# cslr_sys register map
Vendor: Texas Instruments
Peripheral module from a debugger description file (folder C5517).
Address unit: 16 bits
Registers are 16-bit, access not given, reset 0x0 unless marked. A register's access mark holds for its fields unless they carry their own. Offsets are as the file gives them; lines under a group give offsets from that group; [hi:lo] are bit positions; {n}, {i} and the like mark numbered series; 'fields as' and 'values as' point back to an identical list; <NAME> marks a mode.

## SYS — The DSP system module controls several features of the DSP, e.g. clock control, DMA event synchronization, PLL settings, and the CLKOUT source.
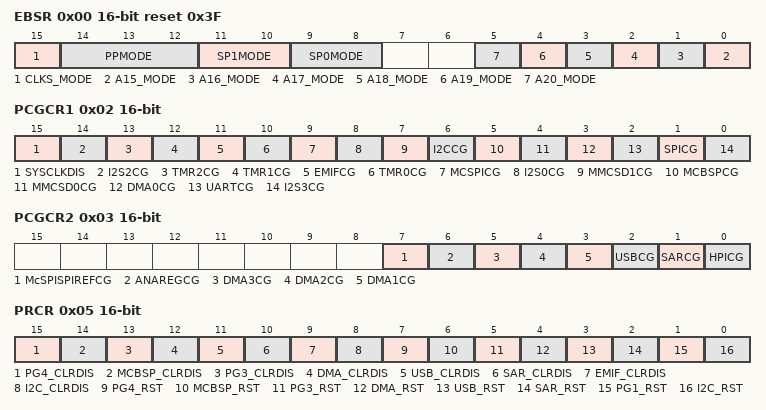
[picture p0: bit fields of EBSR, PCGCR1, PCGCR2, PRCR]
0x00 EBSR reset 0x3F — External Bus Selection Register
  [15] CLKS_MODE ro — McBSP CLKS selection bit.Determines which pin of the McBSP is fed to S05 when the Serial Port 0 Mode is set to 11.
    0=ZERO (McBSP CLKR signal is routed to Serial Port 0 pin S05.); 1=ONE (McBSP CLKS signal is routed to Serial Port 0 pin S05)
  [14:12] PPMODE rw — Parallel port mode bits. These bits control the pin muxing on the parallel port.
    {v}=MODE{v} (v=0..6); 7=MODE7 (Reserved, do not use.)
  [11:10] SP1MODE rw — Serial port 1 mode bits. These bits control the pin muxing on serial port 1.
    0=MODE0; 1=MODE1; 2=MODE2; 3=MODE3 (Mode 3 - Reserved , Do not use.)
  [9:8] SP0MODE rw — Serial port 0 mode bits. These bits control the pin muxing on serial port 0.
    {v}=MODE{v} (v=0..3)
  [n-15] A{n}_MODE rw (n=15..20) — This bit controls the pin multiplexing on EM_A[{n}].
    0=MODE0 (Pin behaves as EM_A[{n}].); 1=MODE1 (Pin behaves as GP[{n+6}].)
0x02 PCGCR1 rw — Peripheral Clock Gating Configuration Register 1
  [15] SYSCLKDIS — System clock disable bit. This bit can be used to turn off the system clock. Setting the WAKEUP pin high enables the system clock. Since the WAKEUP pin is used to re-enable the system clock, the WAKEUP pin must be low to disable the system clock.
    0=ACTIVE (System clock is active.); 1=DISABLED (System clock is disabled.)
  [14] I2S2CG — I2S2 clock gate control bit. This bit is used to enable and disable the I2S2 peripheral clock.
    0=ACTIVE (Peripheral clock is active.); 1=DISABLED (Peripheral clock is disabled.)
  [13] TMR2CG — Timer 2 clock gate control bit. This bit is used to enable and disable the Timer 2 peripheral clock.
    values as I2S2CG
  [12] TMR1CG — Timer 1 clock gate control bit. This bit is used to enable and disable the Timer 1 peripheral clock.
    values as I2S2CG
  [11] EMIFCG — EMIF clock gate control bit. This bit is used to enable and disable the EMIF peripheral clock. NOTE: You must request permission before stopping the EMIF clock through the peripheral clock stop request/acknowledge register (CLKSTOP).
    values as I2S2CG
  [10] TMR0CG — Timer 0 clock gate control bit. This bit is used to enable and disable the Timer 0 peripheral clock.
    values as I2S2CG
  [9] MCSPICG — MCSPI clock gate control bit. This bit is used to enable and disable the MCSPI peripheral clock.
    values as I2S2CG
  [8] I2S0CG — I2S0 clock gate control bit. This bit is used to enable and disable the I2S0 peripheral clock.
    values as I2S2CG
  [7] MMCSD1CG — MMC/SD1 clock gate control bit. This bit is used to enable and disable the MMC/SD1 peripheral clock.
    values as I2S2CG
  [6] I2CCG — I2C clock gate control bit. This bit is used to enable and disable the I2C peripheral clock.
    values as I2S2CG
  [5] MCBSPCG — McBSP clock gate control bit. This bit is used to enable the disable the McBSP peripheral clock
    values as I2S2CG
  [4] MMCSD0CG — MMC/SD0 clock gate control bit. This bit is used to enable and disable the MMC/SD0 peripheral clock.
    values as I2S2CG
  [3] DMA0CG — DMA controller 0 clock gate control bit. This bit is used to enable and disable the peripheral clock the DMA controller 0.
    values as I2S2CG
  [2] UARTCG — UART clock gate control bit. This bit is used to enable and disable the UART peripheral clock. NOTE: You must request permission before stopping the UART clock through the peripheral clock stop request/acknowledge register (CLKSTOP).
    values as I2S2CG
  [1] SPICG — SPI clock gate control bit. This bit is used to enable and disable the SPI controller peripheral clock.
    values as I2S2CG
  [0] I2S3CG — I2S3 clock gate control bit. This bit is used to enable and disable the I2S3 peripheral clock.
    values as I2S2CG
0x03 PCGCR2 — Peripheral Clock Gating Configuration Register 2
  [7] McSPISPIREFCG rw — McSPI SPIREF Clock Gate Control bit. This bit is used to enable and disable the clock to the McSPI SPIREF block.
    values as PCGCR1.I2S2CG
  [6] ANAREGCG rw — Analog registers clock gate control bit. This bit is used to enable and disable the clock to the registers that control the analog domain of the device, i.e. registers in the 7000h-70FFh I/O space address range. NOTE: When SARCG = 0, the clocks to the analog domain registers is enabled regardless of the ANAREGCG setting.
    0=ACTIVE (Clock is active.); 1=DISABLED (Clock is disabled.)
  [5] DMA3CG rw — DMA controller 3 clock gate control bit. This bit is used to enable and disable the peripheral clock the DMA controller 3.
    values as PCGCR1.I2S2CG
  [4] DMA2CG rw — DMA controller 2 clock gate control bit. This bit is used to enable and disable the peripheral clock the DMA controller 2.
    values as PCGCR1.I2S2CG
  [3] DMA1CG rw — DMA controller 1 clock gate control bit. This bit is used to enable and disable the peripheral clock the DMA controller 1.
    values as PCGCR1.I2S2CG
  [2] USBCG rw — USB clock gate control bit. This bit is used to enable and disable the peripheral clock the USB. NOTE: You must request permission before stopping the USB clock through the peripheral clock stop request/acknowledge register (CLKSTOP).
    values as PCGCR1.I2S2CG
  [1] SARCG rw — SAR clock gate control bit. This bit is used to enable and disable the SAR peripheral clock. NOTE: When SARCG = 0, the clocks to the analog domain registers is enabled regardless of the ANAREGCG setting.
    values as PCGCR1.I2S2CG
  [0] HPICG rw — HPI clock gate control bit. This bit is used to enable and disable the HPI peripheral clock.
    values as PCGCR1.I2S2CG
0x04 PSRCR rw — Peripheral Software Reset Counter Register
  [15:0] COUNT — Count bits. These bits specify the number of system clock (SYSCLK) cycles the software reset bits are asserted. When the software counter reaches 0, the software reset bits will be cleared to 0. Always initialize this field with 20h.
0x05 PRCR rw — Peripheral Reset Control Register
  [15] PG4_CLRDIS — Peripheral group 4 self-cleraing software reset disable bit. Drives the HPI, I2S2, I2S3, UART, and SPI reset signal.
    0=ENABLE (self-clearing software reset is enabled.); 1=DISABLE (self-clearing software reset is disabled.)
  [14] MCBSP_CLRDIS — MCBSP self-cleraing software reset disable bit. Drives the MCBSP self-cleraing software reset disable signal.
    values as PG4_CLRDIS
  [13] PG3_CLRDIS — Peripheral group 3 self-cleraing software reset disable bit. Drives the MMC/SD0, MMC/SD1, I2S0, and MCSPI self-cleraing software reset disable signal.
    values as PG4_CLRDIS
  [12] DMA_CLRDIS — DMA self-cleraing software reset disable bit. Drives the self-cleraing software reset disable signal to the DMA controllers.
    values as PG4_CLRDIS
  [11] USB_CLRDIS — USB self-cleraing software reset disable bit. Drives the USB self-cleraing software reset disable signal.
    values as PG4_CLRDIS
  [10] SAR_CLRDIS — Analog registers and SAR self-cleraing software reset disable bit. Drives the analog register and SAR self-cleraing software reset disable signal.
    values as PG4_CLRDIS
  [9] EMIF_CLRDIS — Drives the EMIF self-cleraing software reset disable signal.
    values as PG4_CLRDIS
  [8] I2C_CLRDIS — I2C self-cleraing software reset disable bit. Drives the I2C self-cleraing software reset disable signal.
    values as PG4_CLRDIS
  [7] PG4_RST — Peripheral group 4 software reset bit. Drives the HPI, I2S2, I2S3, UART, and SPI reset signal.
    1=RST (Reset deasserted, modules out of reset.); 0=NRST (Reset asserted, modules in reset.)
  [6] MCBSP_RST — MCBSP software reset bit. Drives the MCBSP reset signal.
    values as PG4_RST
  [5] PG3_RST — Peripheral group 3 software reset bit. Drives the MMC/SD0, MMC/SD1, I2S0, and MCSPI reset signal.
    values as PG4_RST
  [4] DMA_RST — DMA software reset bit. Drives the reset signal to the DMA controllers.
    values as PG4_RST
  [3] USB_RST — USB software reset bit. Drives the USB reset signal.
    1=RST (Reset deasserted, module out of reset.); 0=NRST (Reset asserted, module in reset.)
  [2] SAR_RST — Analog registers and SAR reset bit. Drives the analog register and SAR reset signal.
    values as USB_RST
  [1] PG1_RST — Drives the EMIF and Timer reset signal.
    values as PG4_RST
  [0] I2C_RST — I2C software reset bit. Drives the I2C reset signal.
    values as USB_RST
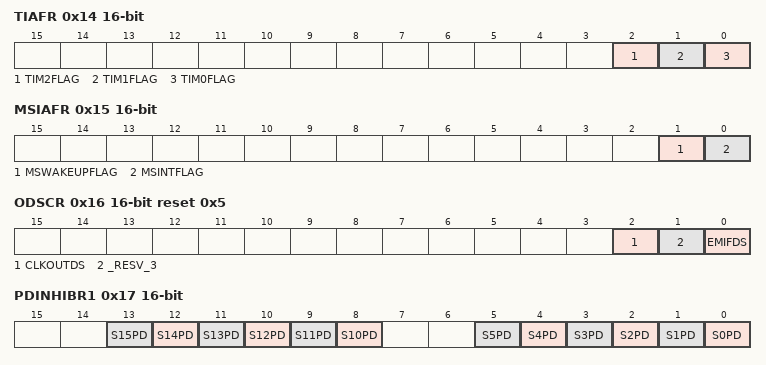
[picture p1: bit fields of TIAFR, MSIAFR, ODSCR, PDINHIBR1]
0x14 TIAFR — Timer Interrupt Aggregation Flag Register
  [all] fields
    0=NOINT (Timer has not generated an interrupt.); 1=INT (Timer interrupt has occurred.)
  [2] TIM2FLAG — Timer 2 interrupt flag bit. This bit latches the timer interrupt signal when the timer counter expires. You can clear this flag bit by writing a 1 to it. (access RW1C)
  [1] TIM1FLAG — Timer 1 interrupt flag bit. This bit latches the timer interrupt signal when the timer counter expires. You can clear this flag bit by writing a 1 to it. (access RW1C)
  [0] TIM0FLAG — Timer 0 interrupt flag bit. This bit latches the timer interrupt signal when the timer counter expires. You can clear this flag bit by writing a 1 to it. (access RW1C)
0x15 MSIAFR — McSPI Interrupt Aggregation Flag Register
  [1] MSWAKEUPFLAG rw — McSPI Wake-Up Interrupt Flag. Connected to McSPI SWAKEUP. Write a 1 to this register to clear the interrupt flag.
    0=NOINT (McSPI has not generated interrupt.); 1=INT (McSPI wake-up interrupt has occurred.)
  [0] MSINTFLAG rw — McSPI Interrupt Flag. Connected to McSPI SInterrupt. Write a 1 to this register to clear the interrupt flag.
    0=NOINT (McSPI has not generated interrupt.); 1=INT (McSPI Sinterrupt has occurred.)
0x16 ODSCR reset 0x5 — Output Drive Strength Control Register
  [2] CLKOUTDS rw — CLKOUT pin output drive strength bits. These bits set the drive strength for the CLKOUT pin.
    0=MIN (Minimum drive strength.); 1=MAX (Maximum drive strength.)
  [1] _RESV_3 — (access N)
  [0] EMIFDS rw — EMIF pin output drive strength bits. These bits set the drive strength for the EMIF pins.
    values as CLKOUTDS
0x17 PDINHIBR1 — Pull-Down Inhibit Register 1
  [all] fields
    0=ENABLE (Pin pull-down is enabled.); 1=DISABLE (Pin pull-down is disabled.)
  [n-2] S{n}PD rw (n=10..15) — Serial port pin {n} pull-down inhibit bit. Setting this bit to 1 disables the pin internal pull-down.
  [n] S{n}PD rw (n=0..5) — Serial port pin {n} pull-down inhibit bit. Setting this bit to 1 disables the pin internal pull-down.
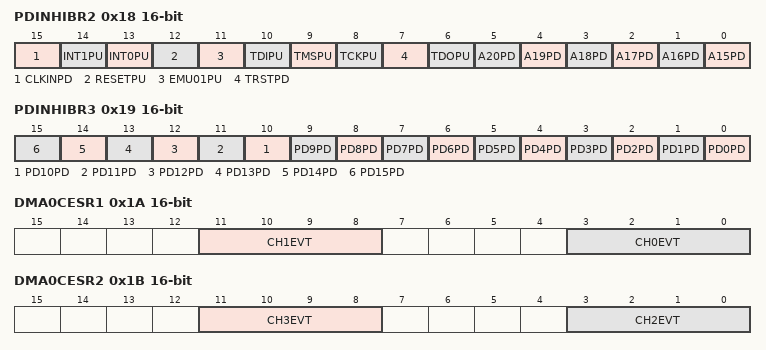
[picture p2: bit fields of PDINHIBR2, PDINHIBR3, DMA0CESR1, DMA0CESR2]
0x18 PDINHIBR2 rw — Pull-Down Inhibit Register 2
  [15] CLKINPD — CLKIN pin pull-down inhibit bit. Setting this bit to 1 disables the pin internal pull-down.
    values as the fields of PDINHIBR1
  [14] INT1PU — Interrupt 1 pin pull-up inhibit bit. Setting this bit to 1 disables the pin internal pull-up.
    0=ENABLE (Pin pull-up is enabled.); 1=DISABLE (Pin pull-up is disabled.)
  [13] INT0PU — Interrupt 0 pin pull-up inhibit bit. Setting this bit to 1 disables the pin internal pull-up.
    values as INT1PU
  [12] RESETPU — Reset pin pull-up inhibit bit. Setting this bit to 1 disables the pin internal pull-up.
    values as INT1PU
  [11] EMU01PU — EMU1 and EMU0 pin pull-up inhibit bit. Setting this bit to 1 disables the pin internal pull-up.
    values as INT1PU
  [10] TDIPU — TDI pin pull-up inhibit bit. Setting this bit to 1 disables the pin internal pull-up.
    values as INT1PU
  [9] TMSPU — TMS pin pull-up inhibit bit. Setting this bit to 1 disables the pin internal pull-up.
    values as INT1PU
  [8] TCKPU — TCK pin pull-up inhibit bit. Setting this bit to 1 disables the pin internal pull-up.
    values as INT1PU
  [7] TRSTPD — TRST pin pull-down inhibit bit. Setting this bit to 1 disables the pin internal pull-down.
    values as the fields of PDINHIBR1
  [6] TDOPU — TDO pin pull-up inhibit bit. Setting this bit to 1 disables the pin internal pull-up.
    values as INT1PU
  [n-15] A{n}PD (n=15..20) — EMIF A[{n}] pin pull-down inhibit bit. Setting this bit to 1 disables the pin internal pull-down.
    values as the fields of PDINHIBR1
0x19 PDINHIBR3 rw — Pull-Down Inhibit Register 3
  [all] fields
    values as the fields of PDINHIBR1
  [n] PD{n}PD (n=0..15) — Parallel port {n} pin pull-down inhibit bit. Setting this bit to 1 disables the pin internal pull-down.
0x1A DMA0CESR1 — Defines the synchronization events for DMA0 channel 1 and 0.
  [11:8] CH1EVT rw — Channel 1 synchronization events. When SYNCMODE = 1 in the channel DMATCR2, the CH1EVT bits in the DMAnCESR registers specify the synchronization event for activity in the DMA controller.
  [3:0] CH0EVT rw — Channel 0 synchronization events. When SYNCMODE = 1 in the channel DMATCR2, the CH0EVT bits in the DMAnCESR registers specify the synchronization event for activity in the DMA controller.
0x1B DMA0CESR2 — Defines the synchronization events for DMA0 channel 3 and 2.
  [11:8] CH3EVT rw — Channel 3 synchronization events. When SYNCMODE = 1 in the channel DMATCR2, the CH3EVT bits in the DMAnCESR registers specify the synchronization event for activity in the DMA controller.
  [3:0] CH2EVT rw — Channel 2 synchronization events. When SYNCMODE = 1 in the channel DMATCR2, the CH2EVT bits in the DMAnCESR registers specify the synchronization event for activity in the DMA controller.
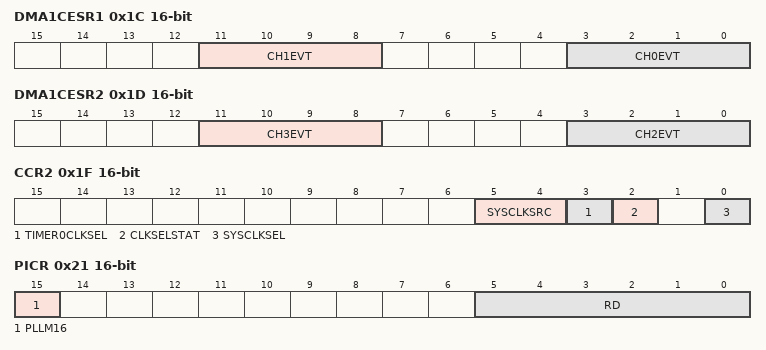
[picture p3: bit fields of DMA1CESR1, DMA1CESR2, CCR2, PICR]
0x1C DMA1CESR1 — Defines the synchronization events for DMA1 channel 1 and 0.
  fields as DMA0CESR1
0x1D DMA1CESR2 — Defines the synchronization events for DMA1 channel 3 and 2.
  fields as DMA0CESR2
0x1E CCR1 — Clock Configuration Register 1
  [15] EORE rw — External Oscillator Resistance Enable.
0x1F CCR2 — Clock Configuration Register 2
  [5:4] SYSCLKSRC ro — System clock source bits. These read-only bits reflect the source for the system clock.
    0=BYPRTC (The system clock generator is in bypass mode; SYSCLK is driven by the RTC oscillator output.); 1=LOCKRTC (The system clock generator is in lock mode; the RTC oscillator output provides the input clock.); 2=BYPCLKIN (The system clock generator is in bypass mode; SYSCLK is driven by CLKIN.); 3=LOCKCLKIN (The system clock generator is in lock mode; the CLKIN pin provides the input clock.)
  [3] TIMER0CLKSEL ro — Timer0 clock source select bit. This bit specifies the input clock to Timer0.
    0=SYSCLK (Timer0 uses SYSCLK as input clock.); 1=PLLOUT (Timer0 uses PLL output clock (PLLOUT) as input clock.)
  [2] CLKSELSTAT ro — CLK_SEL pin status bit. This reflects the state of the CLK_SEL pin.
    0=RTCIN (CLK_SEL pin is low (RTC input clock selected).); 1=CLKIN (CLK_SEL pin is high (CLKIN input clock selected.))
  [0] SYSCLKSEL rw — System clock source select bit. This bit is used to select between the two main clocking modes for the DSP: bypass and lock mode. In bypass mode, the DSP clock generator is byassed and the system clock is set to either CLKIN or the RTC output (as determined by the CLKSEL pin). In lock mode, the system clock is set to the output of the DSP clock generator. Logic in the system clock generator prevents switching from bypass mode to lock mode if the PLL is powered down. After settings SYSCLKSEL = 1, you can check the SYSCLKSRC bits to determine if the system clock generator is in lock mode.
    0=BYPASS (Bypass mode is selected.); 1=LOCK (Lock mode is selected.)
0x20 PMR rw — PLL Multiplier Register
  [15:0] PLLM15_0 — PLL Multiplier [15:0]
0x21 PICR — PLL Input Control Register
  [15] PLLM16 rw — PLL Multiplier [16]
  [5:0] RD rw — Reference input frequency divider. The frequency inputted to the Phase Detector must fall between 1.7MHz and 6.79MHz. These are connected to CLKR[5:0] in PLL027SSP. Divides the input clock rate to the PLL by the following number: 000000 = Divide-by-1 000001 = Divide-by-2. & 111111 = Divide-by-64
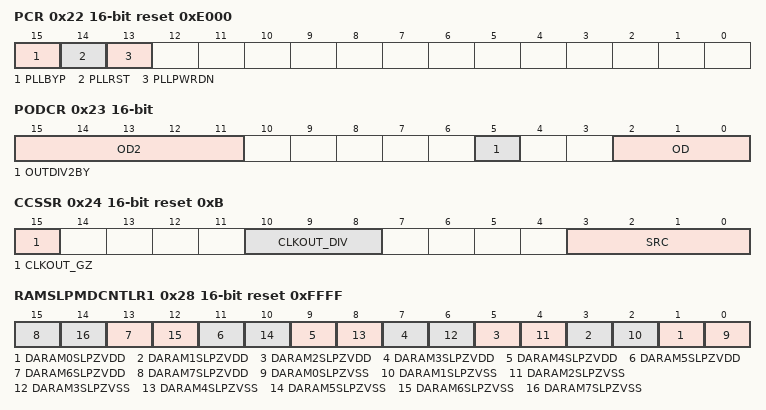
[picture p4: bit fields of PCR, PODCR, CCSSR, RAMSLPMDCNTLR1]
0x22 PCR reset 0xE000 — PLL Control Register
  [15] PLLBYP rw — Bypass PLL. This is connected to BYPASS in PLL027SSP. 0 = PLL is enabled. 1 = PLL is bypassed and VCO is powered down.
    0=NBYP (PLL is enable); 1=BYP (PLL is bypassed)
  [14] PLLRST rw — Resets the PLL and clears the PLL Multiplier and Reference dividers. This is equivalent to activating RESET in PLL027SSP. 0 = PLL is normal operating mode. 1 = PLL is reset
    0=NRST (PLL is in normal operating mode); 1=RST (PLL is reset)
  [13] PLLPWRDN rw — PLL power down. 0 = PLL is powered. 1 = PLL is powered down.
    0=PWRD (PLL is in powered); 1=NPWRD (PLL is powered down)
0x23 PODCR — PLL Output Divider Control Register
  [15:11] OD2 rw — Output Divider 2 value. This is connected to second output divider following PLL027SSP. 00000 = Divide-by-2 00001 = Divide-by-4 00010 = Divide-by-6 00011 = Divide-by-8 ... 11111 = Divide-by-64
  [5] OUTDIV2BY rw — Output Divider 2 Bypass. Bypasses the second output divider 0 = Output Divider 2 is enabled 1 = Output Divider 2 is bypassed
    0=OD2EN (Output divider 2 is enabled); 1=OD2BYP (Output divider 2 is bypassed)
  [2:0] OD — Output Divider value. This is connected to CLKOD[2:0] in PLL027SSP. 000 = Divide-by-1 001 = Divide-by-2. & 111 = Divide-by-8
0x24 CCSSR reset 0xB — CLKOUT Clock Source Register
  [15] CLKOUT_GZ rw — Output Enable for the CLKOUT pin s output buffer: 0 = Output driver is enabled 1 = Output driver is tristated
    0=COEN (Output driver is enabled); 1=COTRI (Output driver is tristated)
  [10:8] CLKOUT_DIV rw — CLKOUT Divider value: 000 = CLKOUT represents the System clock divided by 1 001 = CLKOUT represents the System clock divided by 2 010 = CLKOUT represents the System clock divided by 4 011 = CLKOUT represents the System clock divided by 6 100 = CLKOUT represents the System clock divided by 8 101 = CLKOUT represents the System clock divided by 10 110 = CLKOUT represents the System clock divided by 12 111 = CLKOUT represents the System clock divided by 14
  [3:0] SRC rw — CLKOUT source bits. These bits specify the source clock for the CLKOUT pin.
0x26 ECDR reset 0x1 — EMIF Clock Divider Register
  [0] EDIV rw — EMIF clock divider select bits. The EMIF module can internally divide its input peripheral clock. When this bit is set to 0, the EMIF operates at half the clock rate of its peripheral clock. When this bit is set to 1 the EMIF operates at the full rate of its peripheral clock.
    0=HALFRATE (EMIF operates at half the peripheral clock rate.); 1=FULLRATE (EMIF operates at the same rate as the peripheral clock.)
0x27 RSCR — RTC System Control Register
  [0] RTC_ISO rw — RTC Isolation Control. The reset state of this register is low which isolates the CVDD_RTC power domain from the VDDC power domain. This protects the RTC from corruption when VDDC powers up. The DSP must write a 1 to this register before accessing the RTC registers. DSP software should try to minimize the amount of time while this bit is set high so that the RTC is better protected from VDDC powerdown events. 0 = RTC is isolated. DSP reads/writes to the RTC registers will be blocked. 1 = RTC is not isolated. DSP is able to read/write the RTC registers.
    0=ISO (RTC is isolated.); 1=NISO (RTC is not isolated.)
0x28 RAMSLPMDCNTLR1 rw reset 0xFFFF — RAM Sleep Mode Control Register 1
  [all] fields
    0=ENABLED; 1=DISABLED
  [2n+1] DARAM{n}SLPZVDD (n=0..7) — DARAM{n} SLPZVDD Memory Standby Enable for DARAM{n} 0 = Enable DARAM{n} SLPVDD during memory standby. 1 = Do not enable DARAM{n} SLPVDD during memory standby (normal functional mode).
  [2n] DARAM{n}SLPZVSS (n=0..7) — DARAM{n} SLPZVSS Memory Standby Enable for DARAM{n} 0 = Enable DARAM{n} SLPVSS during memory standby. 1 = Do not enable DARAM{n} SLPVSS during memory standby (normal functional mode).
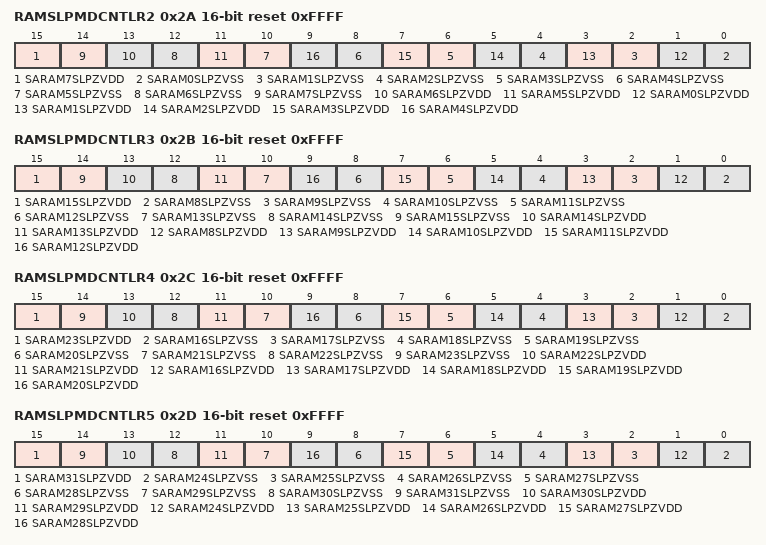
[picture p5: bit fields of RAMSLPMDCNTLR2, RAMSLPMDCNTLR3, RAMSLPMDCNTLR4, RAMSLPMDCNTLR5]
0x2A RAMSLPMDCNTLR2 rw reset 0xFFFF — RAM Sleep Mode Control Register 2
  [all] fields
    0=ENABLED; 1=DISABLED
  [15] SARAM7SLPZVDD — SARAM7 SLPZVDD Memory Standby Enable for SARAM7 0 = Enable SARAM7 SLPVDD during memory standby. 1 = Do not enable SARAM7 SLPVDD during memory standby (normal functional mode).
  [2n] SARAM{n}SLPZVSS (n=0..7) — SARAM{n} SLPZVSS Memory Standby Enable for SARAM{n} 0 = Enable SARAM{n} SLPVSS during memory standby. 1 = Do not enable SARAM{n} SLPVSS during memory standby (normal functional mode).
  [13] SARAM6SLPZVDD — SARAM6 SLPZVDD Memory Standby Enable for SARAM6 0 = Enable SARAM6 SLPVDD during memory standby. 1 = Do not enable SARAM6 SLPVDD during memory standby (normal functional mode).
  [11] SARAM5SLPZVDD — DARAM5 SLPZVDD Memory Standby Enable for DARAM5 0 = Enable DARAM5 SLPVDD during memory standby. 1 = Do not enable DARAM5 SLPVDD during memory standby (normal functional mode).
  [2n+1] SARAM{n}SLPZVDD (n=0..4) — SARAM{n} SLPZVDD Memory Standby Enable for SARAM{n} 0 = Enable SARAM{n} SLPVDD during memory standby. 1 = Do not enable SARAM{n} SLPVDD during memory standby (normal functional mode).
0x2B RAMSLPMDCNTLR3 rw reset 0xFFFF — RAM Sleep Mode Control Register 3
  [all] fields
    0=ENABLED; 1=DISABLED
  [15] SARAM15SLPZVDD — SARAM15 SLPZVDD Memory Standby Enable for SARAM15 0 = Enable SARAM15 SLPVDD during memory standby. 1 = Do not enable SARAM15 SLPVDD during memory standby (normal functional mode).
  [2n-16] SARAM{n}SLPZVSS (n=8..15) — SARAM{n} SLPZVSS Memory Standby Enable for SARAM{n} 0 = Enable SARAM{n} SLPVSS during memory standby. 1 = Do not enable SARAM{n} SLPVSS during memory standby (normal functional mode).
  [13] SARAM14SLPZVDD — SARAM14 SLPZVDD Memory Standby Enable for SARAM14 0 = Enable SARAM14 SLPVDD during memory standby. 1 = Do not enable SARAM14 SLPVDD during memory standby (normal functional mode).
  [11] SARAM13SLPZVDD — DARAM13 SLPZVDD Memory Standby Enable for DARAM13 0 = Enable DARAM13 SLPVDD during memory standby. 1 = Do not enable DARAM13 SLPVDD during memory standby (normal functional mode).
  [2n-15] SARAM{n}SLPZVDD (n=8..12) — SARAM{n} SLPZVDD Memory Standby Enable for SARAM{n} 0 = Enable SARAM{n} SLPVDD during memory standby. 1 = Do not enable SARAM{n} SLPVDD during memory standby (normal functional mode).
0x2C RAMSLPMDCNTLR4 rw reset 0xFFFF — RAM Sleep Mode Control Register 4
  [all] fields
    0=ENABLED; 1=DISABLED
  [15] SARAM23SLPZVDD — SARAM23 SLPZVDD Memory Standby Enable for SARAM23 0 = Enable SARAM23 SLPVDD during memory standby. 1 = Do not enable SARAM23 SLPVDD during memory standby (normal functional mode).
  [2n-32] SARAM{n}SLPZVSS (n=16..23) — SARAM{n} SLPZVSS Memory Standby Enable for SARAM{n} 0 = Enable SARAM{n} SLPVSS during memory standby. 1 = Do not enable SARAM{n} SLPVSS during memory standby (normal functional mode).
  [13] SARAM22SLPZVDD — SARAM22 SLPZVDD Memory Standby Enable for SARAM22 0 = Enable SARAM22 SLPVDD during memory standby. 1 = Do not enable SARAM22 SLPVDD during memory standby (normal functional mode).
  [11] SARAM21SLPZVDD — DARAM21 SLPZVDD Memory Standby Enable for DARAM21 0 = Enable DARAM21 SLPVDD during memory standby. 1 = Do not enable DARAM21 SLPVDD during memory standby (normal functional mode).
  [2n-31] SARAM{n}SLPZVDD (n=16..20) — SARAM{n} SLPZVDD Memory Standby Enable for SARAM{n} 0 = Enable SARAM{n} SLPVDD during memory standby. 1 = Do not enable SARAM{n} SLPVDD during memory standby (normal functional mode).
0x2D RAMSLPMDCNTLR5 rw reset 0xFFFF — RAM Sleep Mode Control Register 5
  [all] fields
    0=ENABLED; 1=DISABLED
  [15] SARAM31SLPZVDD — SARAM31 SLPZVDD Memory Standby Enable for SARAM31 0 = Enable SARAM31 SLPVDD during memory standby. 1 = Do not enable SARAM31 SLPVDD during memory standby (normal functional mode).
  [2n-48] SARAM{n}SLPZVSS (n=24..31) — SARAM{n} SLPZVSS Memory Standby Enable for SARAM{n} 0 = Enable SARAM{n} SLPVSS during memory standby. 1 = Do not enable SARAM{n} SLPVSS during memory standby (normal functional mode).
  [13] SARAM30SLPZVDD — SARAM30 SLPZVDD Memory Standby Enable for SARAM30 0 = Enable SARAM30 SLPVDD during memory standby. 1 = Do not enable SARAM30 SLPVDD during memory standby (normal functional mode).
  [11] SARAM29SLPZVDD — DARAM29 SLPZVDD Memory Standby Enable for DARAM29 0 = Enable DARAM29 SLPVDD during memory standby. 1 = Do not enable DARAM29 SLPVDD during memory standby (normal functional mode).
  [2n-47] SARAM{n}SLPZVDD (n=24..28) — SARAM{n} SLPZVDD Memory Standby Enable for SARAM{n} 0 = Enable SARAM{n} SLPVDD during memory standby. 1 = Do not enable SARAM{n} SLPVDD during memory standby (normal functional mode).
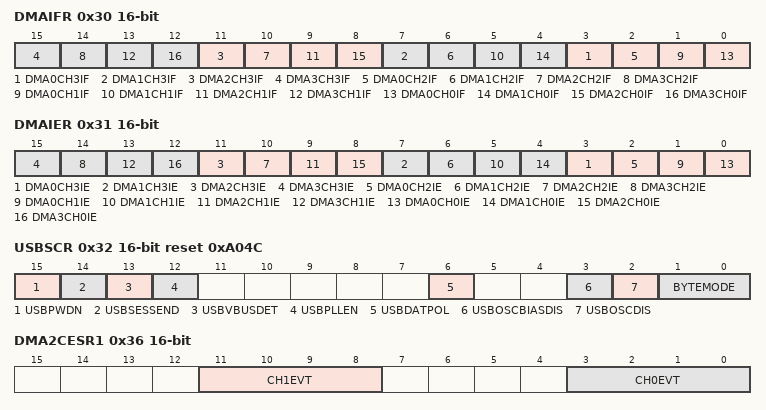
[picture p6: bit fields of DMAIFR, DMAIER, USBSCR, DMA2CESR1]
0x30 DMAIFR rw — Use this register to see which DMA channels have generated interrupts.
  [all] fields
    0=CLEAR (Interrupt has not been generated.); 1=SET (Interrupt has been generated.)
  [4n+3] DMA{n}CH3IF (n=0..3) — DMA controller {n}, channel 3 interrupt status bit.
  [4n+2] DMA{n}CH2IF (n=0..3) — DMA controller {n}, channel 2 interrupt status bit.
  [4n+1] DMA{n}CH1IF (n=0..3) — DMA controller {n}, channel 1 interrupt status bit.
  [4n] DMA{n}CH0IF (n=0..3) — DMA controller {n}, channel 0 interrupt status bit.
0x31 DMAIER rw — Use this register to enabled DMA controller channel interrupts.
  [all] fields
    0=DISABLE (Interrupt is disabled.); 1=ENABLE (Interrupt is enabled.)
  [4n+3] DMA{n}CH3IE (n=0..3) — DMA controller {n}, channel 3 interrupt enable bit.
  [4n+2] DMA{n}CH2IE (n=0..3) — DMA controller {n}, channel 2 interrupt enable bit.
  [4n+1] DMA{n}CH1IE (n=0..3) — DMA controller {n}, channel 1 interrupt enable bit.
  [4n] DMA{n}CH0IE (n=0..3) — DMA controller {n}, channel 0 interrupt enable bit.
0x32 USBSCR reset 0xA04C — USB System Control Register
  [15] USBPWDN rw — USB module power.
    0=POWERED (USB module is powered.); 1=PWRDN (USB module is powered-down.)
  [14] USBSESSEND rw — USB VBUS session end comparator enable.
    0=DISABLED (USB VBUS session end comparator is disabled.); 1=ENABLED (USB VBUS session end comparator is enabled.)
  [13] USBVBUSDET rw — USB VBUS detect enable.
    0=DISABLED (USB VBUS detect comparator is disabled.); 1=ENABLED (USB VBUS detect comparator is enabled.)
  [12] USBPLLEN rw — USB PLL enable.
    0=NORMAL (Normal USB operation.); 1=FORCEON (Override USB suspend end behavior and force release of PLL from suspend state.)
  [6] USBDATPOL rw — USB data polarity bit.
    0=REVERSE (Reverse polarity on DP and DM signals.); 1=NORMAL (Normal polarity.)
  [3] USBOSCBIASDIS rw — USB internal oscillator bias resistor disable.
    0=ENABLED (Internal oscillator bias resistor enabled (normal operating mode).); 1=DISABLED (Internal oscillator bias resistor disabled.)
  [2] USBOSCDIS rw — USB oscillator disable bit.Reset value will be level on CLK_SEL
    0=ENABLED (USB internal oscillator enabled.); 1=DISABLED (USB internal oscillator disabled.)
  [1:0] BYTEMODE rw — USB byte mode select bits.
    0=FULL (Word accesses by the CPU are allowed.); 1=UPPER (Byte accesses by the CPU are allowed (high byte is selected).); 2=LOWER (Byte accesses by the CPU are allowed (low byte is selected).); 3=RSV (Reserved.)
0x33 ESCR — EMIF System Control Register
  [1:0] BYTEMODE rw — EMIF byte mode select bits. These bits control CPU data and program accesses to external memory as well as CPU accesses the EMIF memory-mapped registers.
    values as USBSCR.BYTEMODE
0x34 BMR — Boot Mode Register
  [10:5] BMA ro — Read-only bits that reflect the latched state of the A[20:15] pins on the clock edge after RESETN pin went high. The value is used by the bootloader to determine boot mode. 0 = corresponding I/O pin was latched as LOW. 1 = corresponding I/O pin was latched as HIGH. Reset value will be A[20:15]
0x36 DMA2CESR1 — Defines the synchronization events for DMA2 channel 1 and 0.
  fields as DMA0CESR1
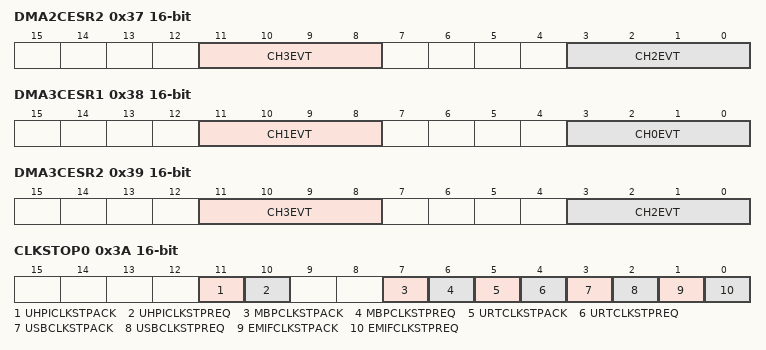
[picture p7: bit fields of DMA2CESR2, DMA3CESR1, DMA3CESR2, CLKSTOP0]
0x37 DMA2CESR2 — Defines the synchronization events for DMA2 channel 3 and 2.
  fields as DMA0CESR2
0x38 DMA3CESR1 — Defines the synchronization events for DMA3 channel 1 and 0.
  fields as DMA0CESR1
0x39 DMA3CESR2 — Defines the synchronization events for DMA3 channel 3 and 2.
  fields as DMA0CESR2
0x3A CLKSTOP0 — Peripheral Clock Stop Request/Acknowledge Register1
  [11] UHPICLKSTPACK ro — UHPI clock stop acknowledge bit. This bit is set to 1 when the UHPI has acknowledged a request for its clock to be stopped. The UHPI clock should not be stopped until this bit is set to 1.
    0=NACK (The request to stop the peripheral clock has not been acknowledged.); 1=ACK (The request to stop the peripheral clock has been acknowledged, the clock can be stopped.)
  [10] UHPICLKSTPREQ rw — UHPI peripheral clock stop request bit. When disabling the UHPI internal peripheral clock, you must set this bit to 1 to request permission to stop the clock. After the UHPI acknowledges the request (UHPICLKSTPACK = 1) you can stop the clock through the peripheral clock gating control register 1 (PCGCR2). When enabling the MCSPI internal clock, enable the clock through PCGCR1, then set UHPICLKSTPREQ to 0.
    0=NREQ (Normal operating mode.); 1=REQ (Request permission to stop the peripheral clock.)
  [7] MBPCLKSTPACK ro — McBSP clock stop acknowledge bit. This bit is set to 1 when the McBSP has acknowledged a request for its clock to be stopped. The McBSP clock should not be stopped until this bit is set to 1.
    values as UHPICLKSTPACK
  [6] MBPCLKSTPREQ rw — McBSP peripheral clock stop request bit. When disabling the McBSP internal peripheral clock, you must set this bit to 1 to request permission to stop the clock. After the McBSP acknowledges the request (MBPCLKSTPACK = 1) you can stop the clock through the peripheral clock gating control register 1 (PCGCR1). When enabling the McBSP internal clock, enable the clock through PCGCR1, then set MBPCKLSTPREQ to 0.
    values as UHPICLKSTPREQ
  [5] URTCLKSTPACK ro — UART clock stop acknowledge bit. This bit is set to 1 when the UART has acknowledged a request for its clock to be stopped. The UART clock should not be stopped until this bit is set to 1.
    values as UHPICLKSTPACK
  [4] URTCLKSTPREQ rw — UART peripheral clock stop request bit. When disabling the UART internal peripheral clock, you must set this bit to 1 to request permission to stop the clock. After the UART acknowledges the request (URTCLKSTPACK = 1) you can stop the clock through the peripheral clock gating control register 1 (PCGCR1). When enabling the UART internal clock, enable the clock through PCGCR1, then set URTCKLSTPREQ to 0.
    values as UHPICLKSTPREQ
  [3] USBCLKSTPACK ro — USB clock stop acknowledge bit. This bit is set to 1 when the USB has acknowledged a request for its clock to be stopped. The USB clock should not be stopped until this bit is set to 1.
    values as UHPICLKSTPACK
  [2] USBCLKSTPREQ rw — USB peripheral clock stop request bit. When disabling the USB internal peripheral clock, you must set this bit to 1 to request permission to stop the clock. After the USB acknowledges the request (USBCLKSTPACK = 1) you can stop the clock through the peripheral clock gating control register 2 (PCGCR2). When enabling the USB internal clock, enable the clock through PCGCR2, then set USBCKLSTPREQ to 0.
    values as UHPICLKSTPREQ
  [1] EMIFCLKSTPACK ro — EMIF clock stop acknowledge bit. This bit is set to 1 when the EMIF has acknowledged a request for its clock to be stopped. The EMIF clock should not be stopped until this bit is set to 1.
    values as UHPICLKSTPACK
  [0] EMIFCLKSTPREQ rw — EMIF peripheral clock stop request bit. When disabling the EMIF internal peripheral clock, you must set this bit to 1 to request permission to stop the clock. After the EMIF acknowledges the request (EMFCLKSTPACK = 1) you can stop the clock through the peripheral clock gating control register 1 (PCGCR1). When enabling the EMIF internal clock, enable the clock through PCGCR1, then set EMFCKLSTPREQ to 0.
    values as UHPICLKSTPREQ
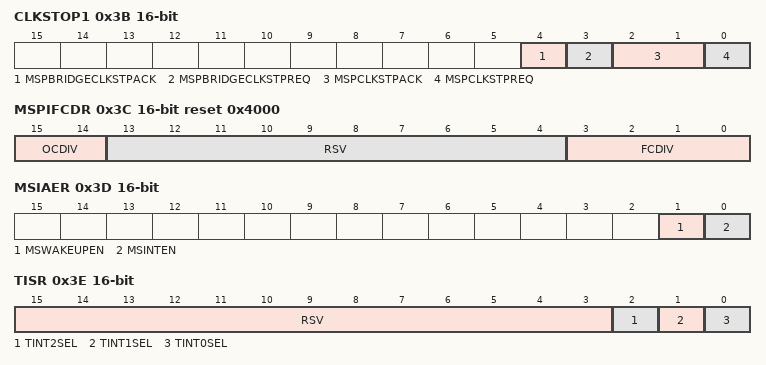
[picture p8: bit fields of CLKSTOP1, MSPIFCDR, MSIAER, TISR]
0x3B CLKSTOP1 — Peripheral Clock Stop Request/Acknowledge Register2
  [4] MSPBRIDGECLKSTPACK ro — MCSPI bridge clock stop acknowledge bit. This bit is set to 1 when the MCSPI bridge has acknowledged a request for its clock to be stopped. The MCSPI bridge clock should not be stopped until this bit is set to 1.
    values as CLKSTOP0.UHPICLKSTPACK
  [3] MSPBRIDGECLKSTPREQ rw — MCSPI bridge peripheral clock stop request bit.
    values as CLKSTOP0.UHPICLKSTPREQ
  [2:1] MSPCLKSTPACK ro — MCSPI clock stop acknowledge bit. This bit is set to 1 when the MCSPI has acknowledged a request for its clock to be stopped. The MCSPI clock should not be stopped until this bit is set to 1.
    values as CLKSTOP0.UHPICLKSTPACK
  [0] MSPCLKSTPREQ rw — MCSPI peripheral clock stop request bit. When disabling the MCSPI internal peripheral clock, you must set this bit to 1 to request permission to stop the clock. After the MCSPI acknowledges the request (MSPCLKSTPACK = 1) you can stop the clock through the peripheral clock gating control register 1 (PCGCR1). When enabling the MCSPI internal clock, enable the clock through PCGCR1, then set MSPCKLSTPREQ to 0.
    values as CLKSTOP0.UHPICLKSTPREQ
0x3C MSPIFCDR access per field reset 0x4000 — Divides the system clock to obtain the functional and OCP clocks
  [15:14] OCDIV rw — Takes the System VBUS Clock and divides it down for the McSPI OCP clock (CLK). 0000 = Divide-by-1 0001 = Divide-by-2 0010 = Divide-by-4 0011 = Reserved
  [13:4] RSV ro — Reserved
  [3:0] FCDIV rw — Takes the System Clock and divides it down for the McSPI functional clock (SPIREFCLK). 0000 = Divide-by-1 0001 = Divide-by-2 0010 = Divide-by-4 0011 = Divide-by-6 0100 = Divide-by-8 0101 = Divide-by-10 0110 = Divide-by-12 0111 = Divide-by-14 1000 = Divide-by-16 1001 = Divide-by-18 1010 = Divide-by-20 1011 = Divide-by-22 1100 = Divide-by-24 1101 = Divide-by-26 1110 = Divide-by-28 1111 = Divide-by-30
0x3D MSIAER — McSPI Interrupt Aggregation Enable Register
  [1] MSWAKEUPEN rw — McSPI Wake-Up Interrupt Enable
    0=DISABLE (McSPI Wake-Up will not interrupt the CPU.); 1=ENABLE (McSPI Wake-Up will be Or ed with other McSPI0 interrupts to the CPU)
  [0] MSINTEN rw — McSPI SInterrupt Enable.
    0=DISABLE (McSPI0 SInterrupt will not interrupt the CPU); 1=ENABLE (McSPI0 Sinterrupt will be Or ed with other McSPI0 interrupts to the CPU.)
0x3E TISR access per field — Timer Interrupt Selection Register
  [15:3] RSV ro — Reserved
  [2] TINT2SEL rw — Timer2 Interrupt Selection 0 = Timer2 interrupt is routed to CPU TINT 1 = Timer2 interrupt is routed to CPU NMI
    0=TINT (Timer2 interrupt is routed to CPU TINT); 1=NMI (Timer2 interrupt is routed to NMI)
  [1] TINT1SEL rw — Timer1 Interrupt Selection 0 = Timer1 interrupt is routed to CPU TINT 1 = Timer1 interrupt is routed to CPU NMI
    0=TINT (Timer1 interrupt is routed to CPU TINT); 1=NMI (Timer1 interrupt is routed to NMI)
  [0] TINT0SEL rw — Timer0 Interrupt Selection 0 = Timer0 interrupt is routed to CPU TINT 1 = Timer0 interrupt is routed to CPU NMI
    0=TINT (Timer0 interrupt is routed to CPU TINT); 1=NMI (Timer0 interrupt is routed to NMI)
0x40 DIEIDR0 ro — Die ID Register 0
  [15:0] DIEID0 — RESERVED.
0x41 DIEIDR1 — Die ID Register 1
  [13:0] DIEID1 ro — RESERVED.
0x42 DIEIDR2 ro — Die ID Register 2
  [15:0] DIEID2 — RESERVED.
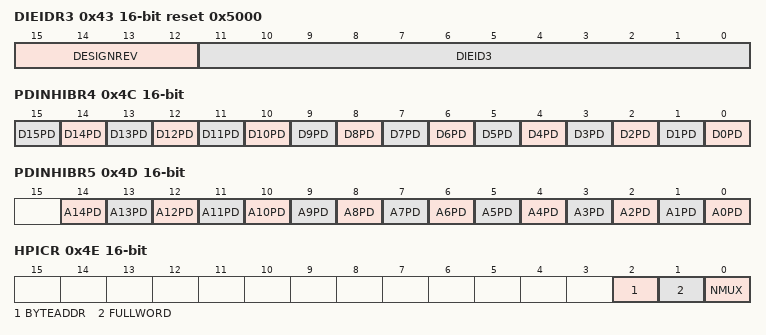
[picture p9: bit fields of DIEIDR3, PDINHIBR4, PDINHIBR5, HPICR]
0x43 DIEIDR3 ro reset 0x5000 — Die ID Register 3
  [15:12] DESIGNREV — Describes the Silicon Revision of Die CPU 0 = Silicon Revision 1.0.
  [11:0] DIEID3 — RESERVED.
0x44 DIEIDR4 — Die ID Register 4
  [5:0] DIEID4 ro — RESERVED.
{0x40+i} DIEIDR{i} (i=5..7) — Die ID Register {i}
0x4C PDINHIBR4 rw — Pull-Down Inhibit Register 4
  [all] fields
    values as the fields of PDINHIBR1
  [n] D{n}PD (n=0..15) — EMIF D[{n}] pin pull-down inhibit bit. Setting this bit to 1 disables the pin internal pull-down.
0x4D PDINHIBR5 — Pull-Down Inhibit Register 5
  [all] fields
    values as the fields of PDINHIBR1
  [n] A{n}PD rw (n=0..14) — EMIF A[{n}] pin pull-down inhibit bit. Setting this bit to 1 disables the pin internal pull-down.
0x4E HPICR — HPI Configuration Register
  [2] BYTEADDR rw — HPI byte/word address mode select. 0 = Host address corresponds to a word (16-bit) address. 1 = Host address corresponds to a byte (8-bit) address.
    0=WORD (Host address corresponds to a word (16-bit) address); 1=BYTE (Host address corresponds to a byte (8-bit) address.)
  [1] FULLWORD rw — HPI dual or half word mode select. 0 = full word (16-bit) operation. This setting needs to be used in conjunction with 16-bit multiplexed mode in the Parallel Port Mode of the External Bus Selection Register. 1 = Double word (32-bit) operation. (Not supported)
    0=16BIT (16 bit mode operation); 1=32BIT (32 bit mode operation(Not supported))
  [0] NMUX rw — HPI multiplexed or non-multiplexed mode select. 0 = HPI uses multiplexed mode. 1 = HPI uses non-multiplexed mode. The EMIF address bus is used as HPI address pins. This setting prevents the EMIF from using the Address and Data pins. (Not supported)
    0=MUX (Mux Mode); 1=NONMUX (Non MUX mode(Not Supported))
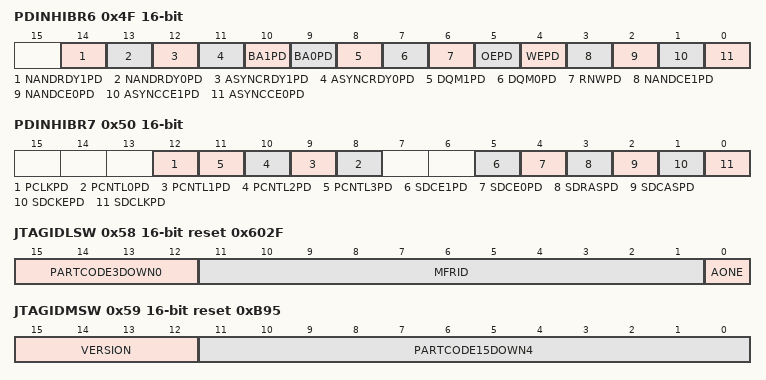
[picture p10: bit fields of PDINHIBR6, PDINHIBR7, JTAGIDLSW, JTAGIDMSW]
0x4F PDINHIBR6 — Pull-Down Inhibit Register 6
  [all] fields
    values as the fields of PDINHIBR1
  [14] NANDRDY1PD rw — EMIF NAND_RDY[1] pin pull-down inhibit bit. Setting this bit to 1 disables the pin internal pull-down.
  [13] NANDRDY0PD rw — EMIF NAND_RDY[0] pin pull-down inhibit bit. Setting this bit to 1 disables the pin internal pull-down.
  [12] ASYNCRDY1PD rw — EMIF ASYNC_RDY[1] pin pull-down inhibit bit. Setting this bit to 1 disables the pin internal pull-down.
  [11] ASYNCRDY0PD rw — EMIF ASYNC_RDY[0] pin pull-down inhibit bit. Setting this bit to 1 disables the pin internal pull-down.
  [10] BA1PD rw — EMIF BA[1] pin pull-down inhibit bit. Setting this bit to 1 disables the pin internal pull-down.
  [9] BA0PD rw — EMIF BA[0] pin pull-down inhibit bit. Setting this bit to 1 disables the pin internal pull-down.
  [8] DQM1PD rw — EMIF DQM[1] pin pull-down inhibit bit. Setting this bit to 1 disables the pin internal pull-down.
  [7] DQM0PD rw — EMIF DQM[0] pin pull-down inhibit bit. Setting this bit to 1 disables the pin internal pull-down.
  [6] RNWPD rw — EMIF RnW pin pull-down inhibit bit. Setting this bit to 1 disables the pin internal pull-down.
  [5] OEPD rw — EMIF OE pin pull-down inhibit bit. Setting this bit to 1 disables the pin internal pull-down.
  [4] WEPD rw — EMIF WE pin pull-down inhibit bit. Setting this bit to 1 disables the pin internal pull-down.
  [3] NANDCE1PD rw — EMIF NAND_CE[1] pin pull-down inhibit bit. Setting this bit to 1 disables the pin internal pull-down.
  [2] NANDCE0PD rw — EMIF NAND_CE[0] pin pull-down inhibit bit. Setting this bit to 1 disables the pin internal pull-down.
  [1] ASYNCCE1PD rw — EMIF ASYNC_CE[1] PD pin pull-down inhibit bit. Setting this bit to 1 disables the pin internal pull-down.
  [0] ASYNCCE0PD rw — EMIF ASYNC_CE[0] PD pin pull-down inhibit bit. Setting this bit to 1 disables the pin internal pull-down.
0x50 PDINHIBR7 — Pull-Down Inhibit Register 7
  [all] fields
    values as the fields of PDINHIBR1
  [12] PCLKPD rw — PCLK pin pull-down inhibit bit. Setting this bit to 1 disables the pin internal pull-down.
  [n+8] PCNTL{n}PD rw (n=0..3) — PCNTL[{n}] pin pull-down inhibit bit. Setting this bit to 1 disables the pin internal pull-down.
  [5] SDCE1PD rw — EMIF SD_CE[1] pin pull-down inhibit bit. Setting this bit to 1 disables the pin internal pull-down.
  [4] SDCE0PD rw — EMIF SD_CE[0] pin pull-down inhibit bit. Setting this bit to 1 disables the pin internal pull-down.
  [3] SDRASPD rw — EMIF SDRAS pin pull-down inhibit bit. Setting this bit to 1 disables the pin internal pull-down.
  [2] SDCASPD rw — EMIF SDCAS pin pull-down inhibit bit. Setting this bit to 1 disables the pin internal pull-down.
  [1] SDCKEPD rw — EMIF SDCKE PD pin pull-down inhibit bit. Setting this bit to 1 disables the pin internal pull-down.
  [0] SDCLKPD rw — EMIF SDCLK PD pin pull-down inhibit bit. Setting this bit to 1 disables the pin internal pull-down.
0x58 JTAGIDLSW ro reset 0x602F — JTAG ID Code LSW Register
  [15:12] PARTCODE3DOWN0 — Part Code number. Read as 0xB956 (unique code within TI assigned to Phoenix)
  [11:1] MFRID — Manufacturer ID number. Read as 0x17 (this is TI s manufacturer ID).
  [0] AONE — A read only bit which will hold a value 1
0x59 JTAGIDMSW ro reset 0xB95 — JTAG ID Code MSW Register
  [15:12] VERSION — Version number. Read as 0x0
  [11:0] PARTCODE15DOWN4 — Part Code number. Read as 0xB956 (unique code within TI assigned to Phoenix)
